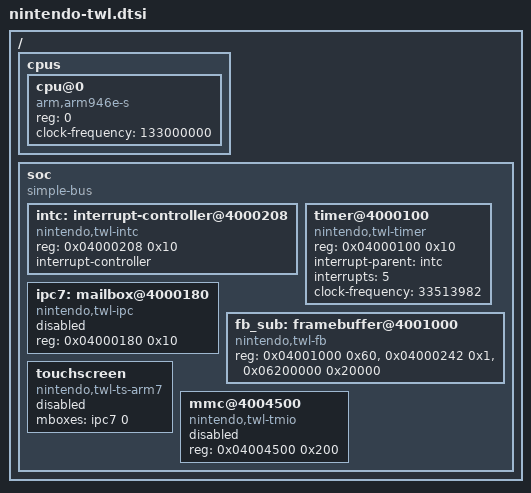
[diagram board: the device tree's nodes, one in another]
// SPDX-License-Identifier: GPL-2.0
//
// nintendo-twl.dtsi — SoC-level template for the Nintendo TWL (DSi) SoC.
//
// Peripheral nodes are stubs (status = "disabled") awaiting kernel drivers.
// Compatible strings use the nintendo,twl-* prefix (Nintendo's internal
// codename for the DSi platform).

/ {
	#address-cells = <1>;
	#size-cells = <1>;

	cpus {
		#address-cells = <1>;
		#size-cells = <0>;

		cpu@0 {
			device_type = "cpu";
			compatible = "arm,arm946e-s";
			reg = <0>;
			clock-frequency = <133000000>;
		};
		// ARM7TDMI co-processor — not a Linux CPU, not represented here.
	};

	soc {
		compatible = "simple-bus";
		#address-cells = <1>;
		#size-cells = <1>;
		ranges;

		intc: interrupt-controller@4000208 {
			compatible = "nintendo,twl-intc";
			// IME @+0x00, IE @+0x08, IF @+0x0C
			reg = <0x04000208 0x10>;
			interrupt-controller;
			#interrupt-cells = <1>;
		};

		timer@4000100 {
			compatible = "nintendo,twl-timer";
			reg = <0x04000100 0x10>;
			interrupt-parent = <&intc>;
			interrupts = <5>;		/* Timer 2 overflow */
			clock-frequency = <33513982>;
		};

		ipc7: mailbox@4000180 {
			compatible = "nintendo,twl-ipc";
			reg = <0x04000180 0x10>;
			#mbox-cells = <1>;
			status = "disabled";
		};

		fb_sub: framebuffer@4001000 {
			compatible = "nintendo,twl-fb";
			reg = <0x04001000 0x60>,	/* sub-engine display regs */
			      <0x04000242 0x1>,		/* VRAMCNT_C               */
			      <0x06200000 0x20000>;	/* VRAM bank C (128 KB)    */
			reg-names = "disp", "vramcnt", "vram";
			status = "okay";
		};

		touchscreen {
			compatible = "nintendo,twl-ts-arm7";
			mboxes = <&ipc7 0>;
			status = "disabled";
		};

		mmc@4004500 {
			// DSi-only TMIO-compatible SD host.
			compatible = "nintendo,twl-tmio";
			reg = <0x04004500 0x200>;
			status = "disabled";
		};
	};
};
